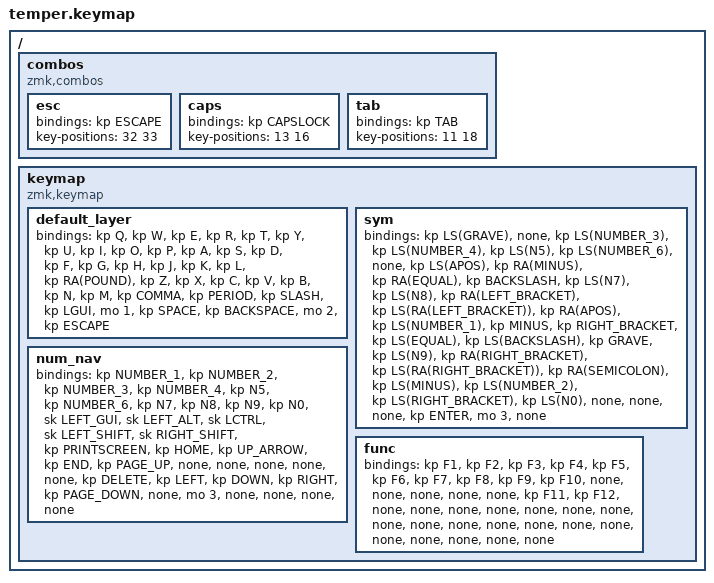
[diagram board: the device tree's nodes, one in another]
/*
 * Copyright (c) 2020 The ZMK Contributors
 *
 * SPDX-License-Identifier: MIT
 */

#include <behaviors.dtsi>
#include <dt-bindings/zmk/keys.h>

/ {
    combos {
        compatible = "zmk,combos";

        esc {
            bindings = <&kp ESCAPE>;
            key-positions = <32 33>;
        };

        caps {
            bindings = <&kp CAPSLOCK>;
            key-positions = <13 16>;
        };

        tab {
            bindings = <&kp TAB>;
            key-positions = <11 18>;
        };
    };

    keymap {
        compatible = "zmk,keymap";

        default_layer {
            bindings = <
&kp Q  &kp W  &kp E  &kp R  &kp T  &kp Y  &kp U  &kp I  &kp O  &kp P  &kp A  &kp S  &kp D  &kp F  &kp G  &kp H  &kp J  &kp K  &kp L  &kp RA(POUND)  &kp Z  &kp X  &kp C  &kp V  &kp B  &kp N  &kp M  &kp COMMA  &kp PERIOD  &kp SLASH  &kp LGUI  &mo 1  &kp SPACE  &kp BACKSPACE  &mo 2  &kp ESCAPE
            >;
        };

        sym {
            bindings = <
&kp LS(GRAVE)  &none  &kp LS(NUMBER_3)  &kp LS(NUMBER_4)  &kp LS(N5)  &kp LS(NUMBER_6)  &none  &kp LS(APOS)  &kp RA(MINUS)  &kp RA(EQUAL)  &kp BACKSLASH  &kp LS(N7)  &kp LS(N8)  &kp RA(LEFT_BRACKET)  &kp LS(RA(LEFT_BRACKET))  &kp RA(APOS)  &kp LS(NUMBER_1)  &kp MINUS  &kp RIGHT_BRACKET  &kp LS(EQUAL)  &kp LS(BACKSLASH)  &kp GRAVE  &kp LS(N9)  &kp RA(RIGHT_BRACKET)  &kp LS(RA(RIGHT_BRACKET))  &kp RA(SEMICOLON)  &kp LS(MINUS)  &kp LS(NUMBER_2)  &kp LS(RIGHT_BRACKET)  &kp LS(N0)  &none  &none  &none  &kp ENTER  &mo 3  &none
            >;
        };

        num_nav {
            bindings = <
&kp NUMBER_1  &kp NUMBER_2  &kp NUMBER_3  &kp NUMBER_4  &kp N5  &kp NUMBER_6  &kp N7  &kp N8  &kp N9  &kp N0  &sk LEFT_GUI  &sk LEFT_ALT  &sk LCTRL  &sk LEFT_SHIFT  &sk RIGHT_SHIFT  &kp PRINTSCREEN  &kp HOME  &kp UP_ARROW  &kp END  &kp PAGE_UP  &none  &none  &none  &none  &none  &kp DELETE  &kp LEFT  &kp DOWN  &kp RIGHT  &kp PAGE_DOWN  &none  &mo 3  &none  &none  &none  &none
            >;
        };

        func {
            bindings = <
&kp F1  &kp F2  &kp F3  &kp F4  &kp F5  &kp F6  &kp F7  &kp F8  &kp F9  &kp F10  &none  &none  &none  &none  &none  &kp F11  &kp F12  &none  &none  &none  &none  &none  &none  &none  &none  &none  &none  &none  &none  &none  &none  &none  &none  &none  &none  &none
            >;
        };
    };
};
